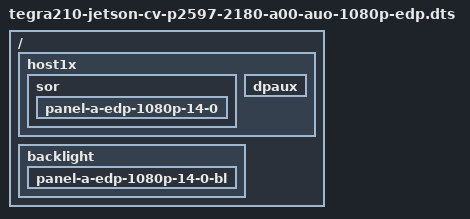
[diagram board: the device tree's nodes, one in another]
/*
 * Copyright (c) 2015-2016, NVIDIA CORPORATION.  All rights reserved.
 *
 * This program is free software; you can redistribute it and/or modify
 * it under the terms of the GNU General Public License as published by
 * the Free Software Foundation; version 2 of the License.
 *
 * This program is distributed in the hope that it will be useful, but WITHOUT
 * ANY WARRANTY; without even the implied warranty of MERCHANTABILITY or
 * FITNESS FOR A PARTICULAR PURPOSE.  See the GNU General Public License for
 * more details.
 *
 * You should have received a copy of the GNU General Public License along
 * with this program; if not, write to the Free Software Foundation, Inc.,
 * 51 Franklin Street, Fifth Floor, Boston, MA  02110-1301, USA.
 *
 */

#include "tegra210-jetson-cv-base-p2597-2180-a00.dts"

/ {
	host1x {
		sor {
			status = "okay";
			panel-a-edp-1080p-14-0 {
				status = "okay";
			};
		};

		dpaux {
			status = "okay";
		};
	};

	backlight {
		panel-a-edp-1080p-14-0-bl {
			status = "okay";
		};
	};
};
